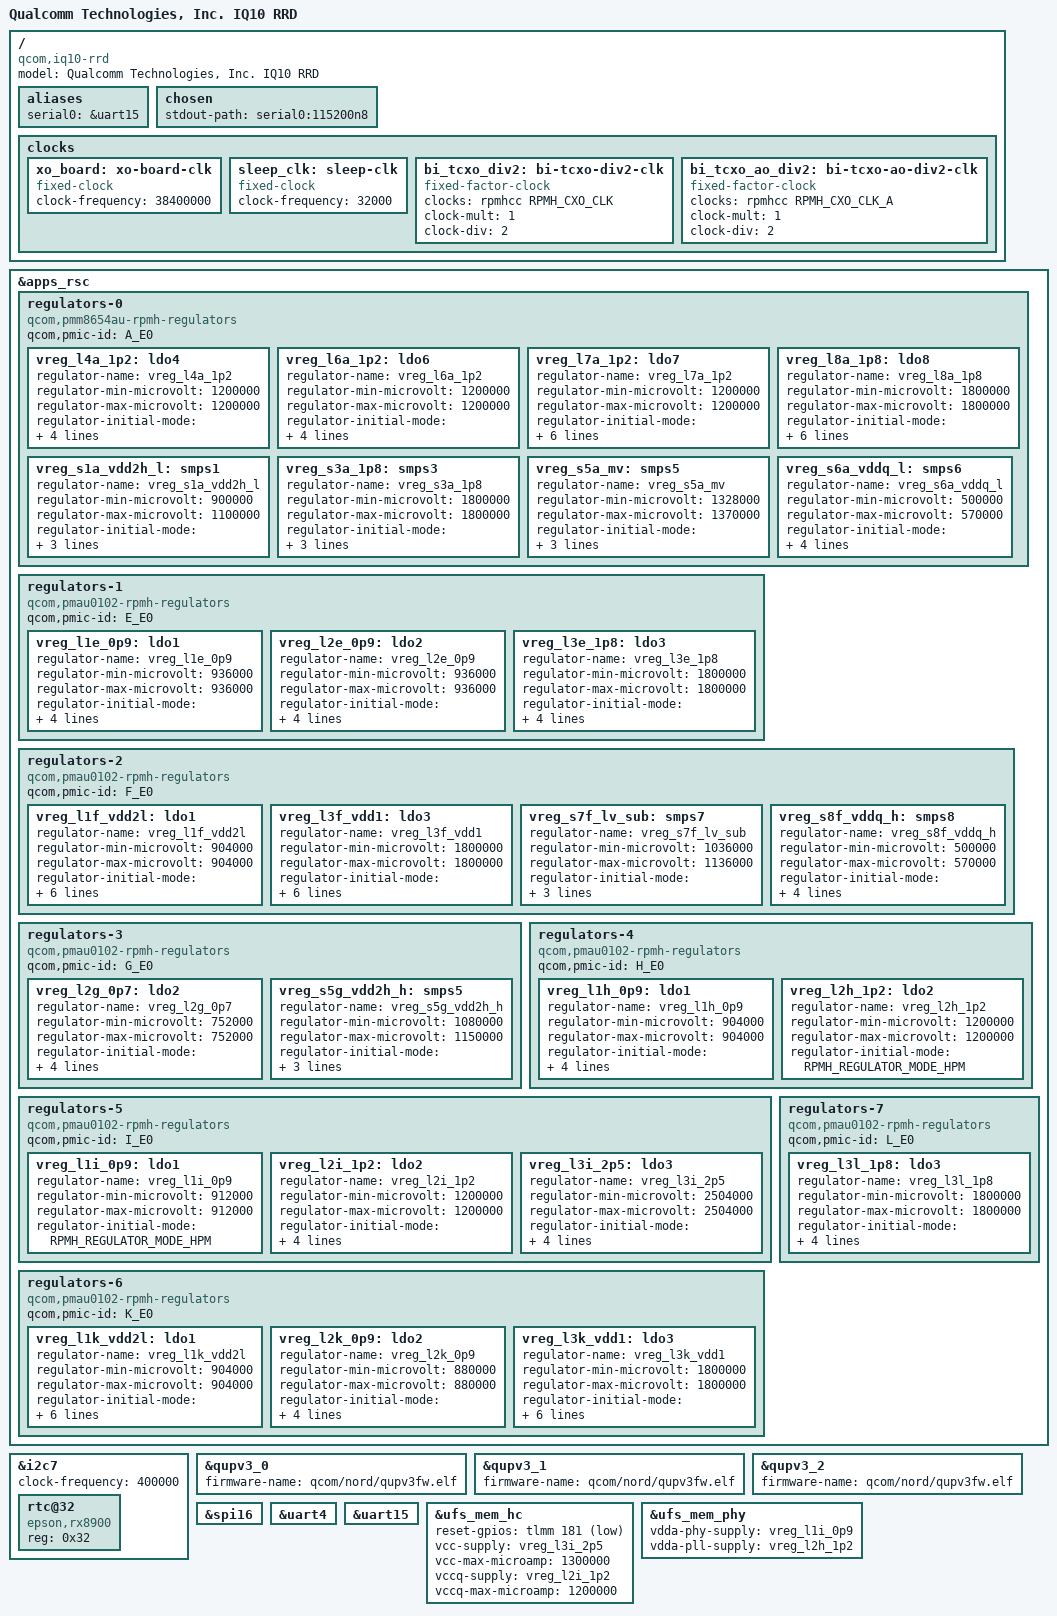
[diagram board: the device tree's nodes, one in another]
// SPDX-License-Identifier: BSD-3-Clause
/*
 * Copyright (c) Qualcomm Technologies, Inc. and/or its subsidiaries.
 */

/dts-v1/;

#include <dt-bindings/gpio/gpio.h>
#include <dt-bindings/regulator/qcom,rpmh-regulator.h>

#include "nord-embedded.dtsi"

/ {
	model = "Qualcomm Technologies, Inc. IQ10 RRD";
	compatible = "qcom,iq10-rrd", "qcom,nord";

	aliases {
		serial0 = &uart15;
	};

	chosen {
		stdout-path = "serial0:115200n8";
	};

	clocks {
		xo_board: xo-board-clk {
			compatible = "fixed-clock";
			clock-frequency = <38400000>;
			#clock-cells = <0>;
		};

		sleep_clk: sleep-clk {
			compatible = "fixed-clock";
			clock-frequency = <32000>;
			#clock-cells = <0>;
		};

		bi_tcxo_div2: bi-tcxo-div2-clk {
			compatible = "fixed-factor-clock";
			#clock-cells = <0>;
			clocks = <&rpmhcc RPMH_CXO_CLK>;
			clock-mult = <1>;
			clock-div = <2>;
		};

		bi_tcxo_ao_div2: bi-tcxo-ao-div2-clk {
			compatible = "fixed-factor-clock";
			#clock-cells = <0>;
			clocks = <&rpmhcc RPMH_CXO_CLK_A>;
			clock-mult = <1>;
			clock-div = <2>;
		};
	};
};

&apps_rsc {
	/* PMIC A - Kobra_MM (PMM8650AU) - SID 0x0, Bus E0 */
	regulators-0 {
		compatible = "qcom,pmm8654au-rpmh-regulators";
		qcom,pmic-id = "A_E0";

		vreg_l4a_1p2: ldo4 {
			regulator-name = "vreg_l4a_1p2";
			regulator-min-microvolt = <1200000>;
			regulator-max-microvolt = <1200000>;
			regulator-initial-mode = <RPMH_REGULATOR_MODE_HPM>;
			regulator-allow-set-load;
			regulator-allowed-modes = <RPMH_REGULATOR_MODE_LPM
						   RPMH_REGULATOR_MODE_HPM>;
		};

		vreg_l6a_1p2: ldo6 {
			regulator-name = "vreg_l6a_1p2";
			regulator-min-microvolt = <1200000>;
			regulator-max-microvolt = <1200000>;
			regulator-initial-mode = <RPMH_REGULATOR_MODE_HPM>;
			regulator-allow-set-load;
			regulator-allowed-modes = <RPMH_REGULATOR_MODE_LPM
						   RPMH_REGULATOR_MODE_HPM>;
		};

		vreg_l7a_1p2: ldo7 {
			regulator-name = "vreg_l7a_1p2";
			regulator-min-microvolt = <1200000>;
			regulator-max-microvolt = <1200000>;
			regulator-initial-mode = <RPMH_REGULATOR_MODE_HPM>;
			regulator-always-on;
			regulator-boot-on;
			regulator-allow-set-load;
			regulator-allowed-modes = <RPMH_REGULATOR_MODE_LPM
						   RPMH_REGULATOR_MODE_HPM>;
		};

		vreg_l8a_1p8: ldo8 {
			regulator-name = "vreg_l8a_1p8";
			regulator-min-microvolt = <1800000>;
			regulator-max-microvolt = <1800000>;
			regulator-initial-mode = <RPMH_REGULATOR_MODE_HPM>;
			regulator-always-on;
			regulator-boot-on;
			regulator-allow-set-load;
			regulator-allowed-modes = <RPMH_REGULATOR_MODE_LPM
						   RPMH_REGULATOR_MODE_HPM>;
		};

		vreg_s1a_vdd2h_l: smps1 {
			regulator-name = "vreg_s1a_vdd2h_l";
			regulator-min-microvolt = <900000>;
			regulator-max-microvolt = <1100000>;
			regulator-initial-mode = <RPMH_REGULATOR_MODE_HPM>;
			regulator-always-on;
			regulator-boot-on;
		};

		vreg_s3a_1p8: smps3 {
			regulator-name = "vreg_s3a_1p8";
			regulator-min-microvolt = <1800000>;
			regulator-max-microvolt = <1800000>;
			regulator-initial-mode = <RPMH_REGULATOR_MODE_HPM>;
			regulator-always-on;
			regulator-boot-on;
		};

		vreg_s5a_mv: smps5 {
			regulator-name = "vreg_s5a_mv";
			regulator-min-microvolt = <1328000>;
			regulator-max-microvolt = <1370000>;
			regulator-initial-mode = <RPMH_REGULATOR_MODE_HPM>;
			regulator-always-on;
			regulator-boot-on;
		};

		vreg_s6a_vddq_l: smps6 {
			regulator-name = "vreg_s6a_vddq_l";
			regulator-min-microvolt = <500000>;
			regulator-max-microvolt = <570000>;
			regulator-initial-mode = <RPMH_REGULATOR_MODE_HPM>;
			regulator-allow-set-load;
			regulator-allowed-modes = <RPMH_REGULATOR_MODE_LPM
						   RPMH_REGULATOR_MODE_HPM>;
		};
	};

	/* PMIC E - Kai_MV - SID 0x4, Bus E0 */
	regulators-1 {
		compatible = "qcom,pmau0102-rpmh-regulators";
		qcom,pmic-id = "E_E0";

		vreg_l1e_0p9: ldo1 {
			regulator-name = "vreg_l1e_0p9";
			regulator-min-microvolt = <936000>;
			regulator-max-microvolt = <936000>;
			regulator-initial-mode = <RPMH_REGULATOR_MODE_HPM>;
			regulator-allow-set-load;
			regulator-allowed-modes = <RPMH_REGULATOR_MODE_LPM
						   RPMH_REGULATOR_MODE_HPM>;
		};

		vreg_l2e_0p9: ldo2 {
			regulator-name = "vreg_l2e_0p9";
			regulator-min-microvolt = <936000>;
			regulator-max-microvolt = <936000>;
			regulator-initial-mode = <RPMH_REGULATOR_MODE_HPM>;
			regulator-allow-set-load;
			regulator-allowed-modes = <RPMH_REGULATOR_MODE_LPM
						   RPMH_REGULATOR_MODE_HPM>;
		};

		vreg_l3e_1p8: ldo3 {
			regulator-name = "vreg_l3e_1p8";
			regulator-min-microvolt = <1800000>;
			regulator-max-microvolt = <1800000>;
			regulator-initial-mode = <RPMH_REGULATOR_MODE_HPM>;
			regulator-allow-set-load;
			regulator-allowed-modes = <RPMH_REGULATOR_MODE_LPM
						   RPMH_REGULATOR_MODE_HPM>;
		};
	};

	/* PMIC F - Kai_MV - SID 0x5, Bus E0 */
	regulators-2 {
		compatible = "qcom,pmau0102-rpmh-regulators";
		qcom,pmic-id = "F_E0";

		vreg_l1f_vdd2l: ldo1 {
			regulator-name = "vreg_l1f_vdd2l";
			regulator-min-microvolt = <904000>;
			regulator-max-microvolt = <904000>;
			regulator-initial-mode = <RPMH_REGULATOR_MODE_HPM>;
			regulator-always-on;
			regulator-boot-on;
			regulator-allow-set-load;
			regulator-allowed-modes = <RPMH_REGULATOR_MODE_LPM
						   RPMH_REGULATOR_MODE_HPM>;
		};

		vreg_l3f_vdd1: ldo3 {
			regulator-name = "vreg_l3f_vdd1";
			regulator-min-microvolt = <1800000>;
			regulator-max-microvolt = <1800000>;
			regulator-initial-mode = <RPMH_REGULATOR_MODE_HPM>;
			regulator-always-on;
			regulator-boot-on;
			regulator-allow-set-load;
			regulator-allowed-modes = <RPMH_REGULATOR_MODE_LPM
						   RPMH_REGULATOR_MODE_HPM>;
		};

		vreg_s7f_lv_sub: smps7 {
			regulator-name = "vreg_s7f_lv_sub";
			regulator-min-microvolt = <1036000>;
			regulator-max-microvolt = <1136000>;
			regulator-initial-mode = <RPMH_REGULATOR_MODE_HPM>;
			regulator-always-on;
			regulator-boot-on;
		};

		vreg_s8f_vddq_h: smps8 {
			regulator-name = "vreg_s8f_vddq_h";
			regulator-min-microvolt = <500000>;
			regulator-max-microvolt = <570000>;
			regulator-initial-mode = <RPMH_REGULATOR_MODE_HPM>;
			regulator-allow-set-load;
			regulator-allowed-modes = <RPMH_REGULATOR_MODE_LPM
						   RPMH_REGULATOR_MODE_HPM>;
		};
	};

	/* PMIC G - Kai_MV - SID 0x6, Bus E0 */
	regulators-3 {
		compatible = "qcom,pmau0102-rpmh-regulators";
		qcom,pmic-id = "G_E0";

		vreg_l2g_0p7: ldo2 {
			regulator-name = "vreg_l2g_0p7";
			regulator-min-microvolt = <752000>;
			regulator-max-microvolt = <752000>;
			regulator-initial-mode = <RPMH_REGULATOR_MODE_HPM>;
			regulator-allow-set-load;
			regulator-allowed-modes = <RPMH_REGULATOR_MODE_LPM
						   RPMH_REGULATOR_MODE_HPM>;
		};

		vreg_s5g_vdd2h_h: smps5 {
			regulator-name = "vreg_s5g_vdd2h_h";
			regulator-min-microvolt = <1080000>;
			regulator-max-microvolt = <1150000>;
			regulator-initial-mode = <RPMH_REGULATOR_MODE_HPM>;
			regulator-always-on;
			regulator-boot-on;
		};
	};

	/* PMIC H - Kai_MV - SID 0x7, Bus E0 */
	regulators-4 {
		compatible = "qcom,pmau0102-rpmh-regulators";
		qcom,pmic-id = "H_E0";

		vreg_l1h_0p9: ldo1 {
			regulator-name = "vreg_l1h_0p9";
			regulator-min-microvolt = <904000>;
			regulator-max-microvolt = <904000>;
			regulator-initial-mode = <RPMH_REGULATOR_MODE_HPM>;
			regulator-allow-set-load;
			regulator-allowed-modes = <RPMH_REGULATOR_MODE_LPM
						   RPMH_REGULATOR_MODE_HPM>;
		};

		vreg_l2h_1p2: ldo2 {
			regulator-name = "vreg_l2h_1p2";
			regulator-min-microvolt = <1200000>;
			regulator-max-microvolt = <1200000>;
			regulator-initial-mode = <RPMH_REGULATOR_MODE_HPM>;
		};
	};

	/* PMIC I - Kai_MV - SID 0x8, Bus E0 */
	regulators-5 {
		compatible = "qcom,pmau0102-rpmh-regulators";
		qcom,pmic-id = "I_E0";

		vreg_l1i_0p9: ldo1 {
			regulator-name = "vreg_l1i_0p9";
			regulator-min-microvolt = <912000>;
			regulator-max-microvolt = <912000>;
			regulator-initial-mode = <RPMH_REGULATOR_MODE_HPM>;
		};

		vreg_l2i_1p2: ldo2 {
			regulator-name = "vreg_l2i_1p2";
			regulator-min-microvolt = <1200000>;
			regulator-max-microvolt = <1200000>;
			regulator-initial-mode = <RPMH_REGULATOR_MODE_HPM>;
			regulator-allow-set-load;
			regulator-allowed-modes = <RPMH_REGULATOR_MODE_LPM
						   RPMH_REGULATOR_MODE_HPM>;
		};

		vreg_l3i_2p5: ldo3 {
			regulator-name = "vreg_l3i_2p5";
			regulator-min-microvolt = <2504000>;
			regulator-max-microvolt = <2504000>;
			regulator-initial-mode = <RPMH_REGULATOR_MODE_HPM>;
			regulator-allow-set-load;
			regulator-allowed-modes = <RPMH_REGULATOR_MODE_LPM
						   RPMH_REGULATOR_MODE_HPM>;
		};
	};

	/* PMIC K - Kai_MV - SID 0xA, Bus E0 */
	regulators-6 {
		compatible = "qcom,pmau0102-rpmh-regulators";
		qcom,pmic-id = "K_E0";

		vreg_l1k_vdd2l: ldo1 {
			regulator-name = "vreg_l1k_vdd2l";
			regulator-min-microvolt = <904000>;
			regulator-max-microvolt = <904000>;
			regulator-initial-mode = <RPMH_REGULATOR_MODE_HPM>;
			regulator-always-on;
			regulator-boot-on;
			regulator-allow-set-load;
			regulator-allowed-modes = <RPMH_REGULATOR_MODE_LPM
						   RPMH_REGULATOR_MODE_HPM>;
		};

		vreg_l2k_0p9: ldo2 {
			regulator-name = "vreg_l2k_0p9";
			regulator-min-microvolt = <880000>;
			regulator-max-microvolt = <880000>;
			regulator-initial-mode = <RPMH_REGULATOR_MODE_HPM>;
			regulator-allow-set-load;
			regulator-allowed-modes = <RPMH_REGULATOR_MODE_LPM
						   RPMH_REGULATOR_MODE_HPM>;
		};

		vreg_l3k_vdd1: ldo3 {
			regulator-name = "vreg_l3k_vdd1";
			regulator-min-microvolt = <1800000>;
			regulator-max-microvolt = <1800000>;
			regulator-initial-mode = <RPMH_REGULATOR_MODE_HPM>;
			regulator-always-on;
			regulator-boot-on;
			regulator-allow-set-load;
			regulator-allowed-modes = <RPMH_REGULATOR_MODE_LPM
						   RPMH_REGULATOR_MODE_HPM>;
		};
	};

	/* PMIC L - Kai_MV - SID 0xB, Bus E0 */
	regulators-7 {
		compatible = "qcom,pmau0102-rpmh-regulators";
		qcom,pmic-id = "L_E0";

		vreg_l3l_1p8: ldo3 {
			regulator-name = "vreg_l3l_1p8";
			regulator-min-microvolt = <1800000>;
			regulator-max-microvolt = <1800000>;
			regulator-initial-mode = <RPMH_REGULATOR_MODE_HPM>;
			regulator-allow-set-load;
			regulator-allowed-modes = <RPMH_REGULATOR_MODE_LPM
						   RPMH_REGULATOR_MODE_HPM>;
		};
	};
};

&i2c7 {
	clock-frequency = <400000>;

	status = "okay";

	rtc@32 {
		compatible = "epson,rx8900";
		reg = <0x32>;
	};
};

&qupv3_0 {
	firmware-name = "qcom/nord/qupv3fw.elf";

	status = "okay";
};

&qupv3_1 {
	firmware-name = "qcom/nord/qupv3fw.elf";

	status = "okay";
};

&qupv3_2 {
	firmware-name = "qcom/nord/qupv3fw.elf";

	status = "okay";
};

&spi16 {
	status = "okay";
};

&uart4 {
	status = "okay";
};

&uart15 {
	status = "okay";
};

&ufs_mem_hc {
	reset-gpios = <&tlmm 181 GPIO_ACTIVE_LOW>;

	vcc-supply = <&vreg_l3i_2p5>;
	vcc-max-microamp = <1300000>;
	vccq-supply = <&vreg_l2i_1p2>;
	vccq-max-microamp = <1200000>;

	status = "okay";
};

&ufs_mem_phy {
	vdda-phy-supply = <&vreg_l1i_0p9>;
	vdda-pll-supply = <&vreg_l2h_1p2>;

	status = "okay";
};
